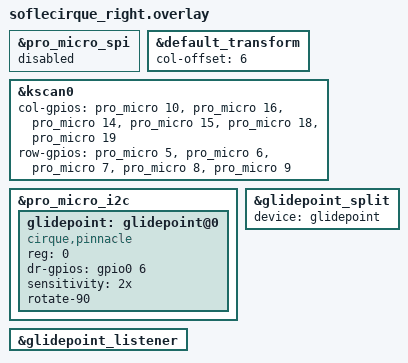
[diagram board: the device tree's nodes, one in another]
#include "soflecirque.dtsi"
#include <dt-bindings/zmk/input_transform.h>
#include <dt-bindings/zmk/matrix_transform.h>



&pro_micro_spi {
    status = "disabled";
};

&default_transform {
    col-offset = <6>;
};

&kscan0 {
    col-gpios
        = <&pro_micro 10 GPIO_ACTIVE_HIGH>
        , <&pro_micro 16 GPIO_ACTIVE_HIGH>
        , <&pro_micro 14 GPIO_ACTIVE_HIGH>
        , <&pro_micro 15 GPIO_ACTIVE_HIGH>
        , <&pro_micro 18 GPIO_ACTIVE_HIGH>
        , <&pro_micro 19 GPIO_ACTIVE_HIGH>
        ;

        row-gpios
            = <&pro_micro 5 (GPIO_ACTIVE_HIGH | GPIO_PULL_DOWN)>
            , <&pro_micro 6 (GPIO_ACTIVE_HIGH | GPIO_PULL_DOWN)>
            , <&pro_micro 7 (GPIO_ACTIVE_HIGH | GPIO_PULL_DOWN)>
            , <&pro_micro 8 (GPIO_ACTIVE_HIGH | GPIO_PULL_DOWN)>
            , <&pro_micro 9 (GPIO_ACTIVE_HIGH | GPIO_PULL_DOWN)>
            ;
};


&pro_micro_i2c {
    status = "okay";

    glidepoint:  glidepoint@0 {
        compatible = "cirque,pinnacle";
        reg = <0>;
        status = "okay";
        dr-gpios = <&gpio0 6 (GPIO_ACTIVE_HIGH)>;
        //default driver options
        sensitivity = "2x"; //1x, 2x, 3x, 4x
        rotate-90;
 

        // Optional: turning this on enables very aggressive power saving, after 5 seconds with no touches
        // the trackpad will go to sleep.  It wakes up on touch, but there is a ~300ms delay.  Most users will find
        // the standard behavior of 'put to sleep when zmk enters idle state (30 seconds without a keypress) feels better.
	    //sleep;
		
		//x-invert;
        //y-invert;
        //no-secondary-tap;
        //no-taps;
        //x-axis-z-min = 5; //default 5, malformed value error
        //y-axis-z-min = 4; // default 4, malformed value error
 
    };
};

&glidepoint_split {
    device = <&glidepoint>;
};

&glidepoint_listener {
    status = "okay";

    // Optional
    // input-processors = <&zip_xy_transform (INPUT_TRANSFORM_XY_SWAP | INPUT_TRANSFORM_X_INVERT | INPUT_TRANSFORM_Y_INVERT)>;
};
